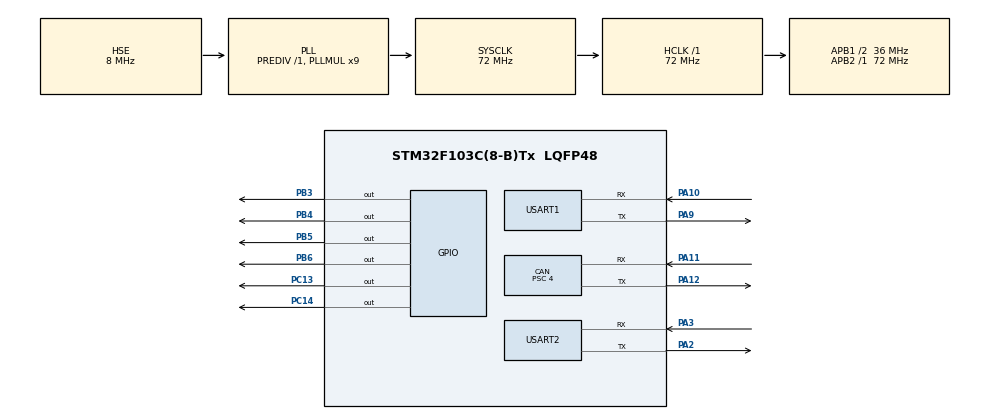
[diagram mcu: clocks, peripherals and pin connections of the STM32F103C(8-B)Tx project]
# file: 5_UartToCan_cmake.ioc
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CAN.ABOM=ENABLE
CAN.BS1=CAN_BS1_13TQ
CAN.BS2=CAN_BS2_4TQ
CAN.CalculateBaudRate=500000
CAN.CalculateTimeBit=2000
CAN.CalculateTimeQuantum=111.11111111111111
CAN.NART=ENABLE
CAN.Prescaler=4
CAN.SJW=CAN_SJW_1TQ
CAN.TXFP=ENABLE
FREERTOS.Queues01=UartRxQueue,128,uint8_t,0,Dynamic,NULL,NULL;CanCmdQueue,128,CanCmd_t,0,Dynamic,NULL,NULL
FREERTOS.Tasks01=Heart_Ta,8,128,Start_Heart_Ta,Default,NULL,Static,Heart_TaBuffer,Heart_TaControlBlock;UartRx_Ta,24,256,Start_UartRx_Ta,Default,NULL,Static,UartRx_TaBuffer,UartRx_TaControlBlock;CanTx_Ta,24,256,Start_CanTx_Ta,Default,NULL,Static,CanTx_TaBuffer,CanTx_TaControlBlock
Mcu.Family=STM32F1
Mcu.Name=STM32F103C(8-B)Tx
Mcu.Package=LQFP48
NVIC.PriorityGroup=NVIC_PRIORITYGROUP_4
NVIC.TIM4_IRQn=true\:15\:0\:false\:false\:true\:false\:false\:true\:true
NVIC.TimeBase=TIM4_IRQn
NVIC.TimeBaseIP=TIM4
NVIC.USART1_IRQn=true\:5\:0\:false\:false\:true\:true\:true\:true\:true
NVIC.USART2_IRQn=true\:5\:0\:false\:false\:true\:true\:true\:true\:true
NVIC.USB_HP_CAN1_TX_IRQn=true\:5\:0\:false\:false\:true\:true\:true\:true\:true
NVIC.USB_LP_CAN1_RX0_IRQn=true\:5\:0\:false\:false\:true\:true\:true\:true\:true
PA10.Mode=Asynchronous
PA10.Signal=USART1_RX
PA11.Mode=CAN_Activate
PA11.Signal=CAN_RX
PA12.Mode=CAN_Activate
PA12.Signal=CAN_TX
PA13.Mode=Serial_Wire
PA13.Signal=SYS_JTMS-SWDIO
PA14.Mode=Serial_Wire
PA14.Signal=SYS_JTCK-SWCLK
PA2.Mode=Asynchronous
PA2.Signal=USART2_TX
PA3.Mode=Asynchronous
PA3.Signal=USART2_RX
PA9.Mode=Asynchronous
PA9.Signal=USART1_TX
PB3.PinState=GPIO_PIN_SET
PB3.Signal=GPIO_Output
PB4.PinState=GPIO_PIN_SET
PB4.Signal=GPIO_Output
PB5.PinState=GPIO_PIN_SET
PB5.Signal=GPIO_Output
PB6.PinState=GPIO_PIN_SET
PB6.Signal=GPIO_Output
PC13-TAMPER-RTC.PinState=GPIO_PIN_SET
PC13-TAMPER-RTC.Signal=GPIO_Output
PC14-OSC32_IN.PinState=GPIO_PIN_SET
PC14-OSC32_IN.Signal=GPIO_Output
PD0-OSC_IN.Mode=HSE-External-Oscillator
PD0-OSC_IN.Signal=RCC_OSC_IN
PD1-OSC_OUT.Mode=HSE-External-Oscillator
PD1-OSC_OUT.Signal=RCC_OSC_OUT
ProjectManager.HeapSize=0x200
ProjectManager.StackSize=0x800
ProjectManager.TargetToolchain=CMake
RCC.AHBFreq_Value=72000000
RCC.APB1CLKDivider=RCC_HCLK_DIV2
RCC.APB1Freq_Value=36000000
RCC.APB1TimFreq_Value=72000000
RCC.APB2Freq_Value=72000000
RCC.APB2TimFreq_Value=72000000
RCC.EnbaleCSS=true
RCC.HCLKFreq_Value=72000000
RCC.PLLMUL=RCC_PLL_MUL9
RCC.PLLSourceVirtual=RCC_PLLSOURCE_HSE
RCC.SYSCLKFreq_VALUE=72000000
RCC.SYSCLKSource=RCC_SYSCLKSOURCE_PLLCLK
RCC.USBFreq_Value=72000000
USART1.VirtualMode=VM_ASYNC
USART2.VirtualMode=VM_ASYNC
VP_FREERTOS_VS_CMSIS_V2.Mode=CMSIS_V2
VP_SYS_VS_tim4.Mode=TIM4
board=custom

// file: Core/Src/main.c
/* USER CODE BEGIN Header */
/**
  ******************************************************************************
  * @file           : main.c
  * @brief          : Main program body
  ******************************************************************************
  * @attention
  *
  * Copyright (c) 2025 STMicroelectronics.
  * All rights reserved.
  *
  * This software is licensed under terms that can be found in the LICENSE file
  * in the root directory of this software component.
  * If no LICENSE file comes with this software, it is provided AS-IS.
  *
  ******************************************************************************
  */
/* USER CODE END Header */
#include "main.h"
#include "cmsis_os.h"
#include "can.h"
#include "usart.h"
#include "gpio.h"

/* USER CODE BEGIN Includes */
#include "app_task.h" // 新增：包含 app_task.h
/* USER CODE END Includes */

void SystemClock_Config(void);
void MX_FREERTOS_Init(void);

int main(void)
{

  /* MCU Configuration--------------------------------------------------------*/

  /* Reset of all peripherals, Initializes the Flash interface and the Systick. */
  HAL_Init();

  /* Configure the system clock */
  SystemClock_Config();

  /* Initialize all configured peripherals */
  MX_GPIO_Init();
  MX_CAN_Init();
  MX_USART1_UART_Init();
  MX_USART2_UART_Init();

  /* Init scheduler */
  osKernelInitialize();  /* Call init function for freertos objects (in cmsis_os2.c) */
  MX_FREERTOS_Init();

  /* Start scheduler */
  osKernelStart();

  /* We should never get here as control is now taken by the scheduler */

  /* Infinite loop */
  while (1)
  {

  }
}

void SystemClock_Config(void)
{
  RCC_OscInitTypeDef RCC_OscInitStruct = {0};
  RCC_ClkInitTypeDef RCC_ClkInitStruct = {0};

  /** Initializes the RCC Oscillators according to the specified parameters
  * in the RCC_OscInitTypeDef structure.
  */
  RCC_OscInitStruct.OscillatorType = RCC_OSCILLATORTYPE_HSE;
  RCC_OscInitStruct.HSEState = RCC_HSE_ON;
  RCC_OscInitStruct.HSEPredivValue = RCC_HSE_PREDIV_DIV1;
  RCC_OscInitStruct.HSIState = RCC_HSI_ON;
  RCC_OscInitStruct.PLL.PLLState = RCC_PLL_ON;
  RCC_OscInitStruct.PLL.PLLSource = RCC_PLLSOURCE_HSE;
  RCC_OscInitStruct.PLL.PLLMUL = RCC_PLL_MUL9;
  if (HAL_RCC_OscConfig(&RCC_OscInitStruct) != HAL_OK)
  {
    Error_Handler();
  }

  /** Initializes the CPU, AHB and APB buses clocks
  */
  RCC_ClkInitStruct.ClockType = RCC_CLOCKTYPE_HCLK|RCC_CLOCKTYPE_SYSCLK
                              |RCC_CLOCKTYPE_PCLK1|RCC_CLOCKTYPE_PCLK2;
  RCC_ClkInitStruct.SYSCLKSource = RCC_SYSCLKSOURCE_PLLCLK;
  RCC_ClkInitStruct.AHBCLKDivider = RCC_SYSCLK_DIV1;
  RCC_ClkInitStruct.APB1CLKDivider = RCC_HCLK_DIV2;
  RCC_ClkInitStruct.APB2CLKDivider = RCC_HCLK_DIV1;

  if (HAL_RCC_ClockConfig(&RCC_ClkInitStruct, FLASH_LATENCY_2) != HAL_OK)
  {
    Error_Handler();
  }

  /** Enables the Clock Security System
  */
  HAL_RCC_EnableCSS();
}

void HAL_TIM_PeriodElapsedCallback(TIM_HandleTypeDef *htim)
{
  if (htim->Instance == TIM4)
  {
    HAL_IncTick();
  }
}

void Error_Handler(void)
{
  __disable_irq();
  while (1)
  {
  }
}

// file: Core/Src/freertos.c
/* USER CODE BEGIN Header */
/**
  ******************************************************************************
  * File Name          : freertos.c
  * Description        : Code for freertos applications
  ******************************************************************************
  * @attention
  *
  * Copyright (c) 2025 STMicroelectronics.
  * All rights reserved.
  *
  * This software is licensed under terms that can be found in the LICENSE file
  * in the root directory of this software component.
  * If no LICENSE file comes with this software, it is provided AS-IS.
  *
  ******************************************************************************
  */
/* USER CODE END Header */

#include "FreeRTOS.h"
#include "task.h"
#include "main.h"
#include "cmsis_os.h"

/* USER CODE BEGIN Includes */

#include "app_task.h"

/* USER CODE END Includes */

typedef StaticTask_t osStaticThreadDef_t;

/* Definitions for Heart_Ta */
osThreadId_t Heart_TaHandle;
uint32_t Heart_TaBuffer[ 128 ];
osStaticThreadDef_t Heart_TaControlBlock;
const osThreadAttr_t Heart_Ta_attributes = {
  .name = "Heart_Ta",
  .cb_mem = &Heart_TaControlBlock,
  .cb_size = sizeof(Heart_TaControlBlock),
  .stack_mem = &Heart_TaBuffer[0],
  .stack_size = sizeof(Heart_TaBuffer),
  .priority = (osPriority_t) osPriorityLow,
};
/* Definitions for UartRx_Ta */
osThreadId_t UartRx_TaHandle;
uint32_t UartRx_TaBuffer[ 256 ];
osStaticThreadDef_t UartRx_TaControlBlock;
const osThreadAttr_t UartRx_Ta_attributes = {
  .name = "UartRx_Ta",
  .cb_mem = &UartRx_TaControlBlock,
  .cb_size = sizeof(UartRx_TaControlBlock),
  .stack_mem = &UartRx_TaBuffer[0],
  .stack_size = sizeof(UartRx_TaBuffer),
  .priority = (osPriority_t) osPriorityNormal,
};
/* Definitions for CanTx_Ta */
osThreadId_t CanTx_TaHandle;
uint32_t CanTx_TaBuffer[ 256 ];
osStaticThreadDef_t CanTx_TaControlBlock;
const osThreadAttr_t CanTx_Ta_attributes = {
  .name = "CanTx_Ta",
  .cb_mem = &CanTx_TaControlBlock,
  .cb_size = sizeof(CanTx_TaControlBlock),
  .stack_mem = &CanTx_TaBuffer[0],
  .stack_size = sizeof(CanTx_TaBuffer),
  .priority = (osPriority_t) osPriorityNormal,
};
/* Definitions for UartRxQueue */
osMessageQueueId_t UartRxQueueHandle;
const osMessageQueueAttr_t UartRxQueue_attributes = {
  .name = "UartRxQueue"
};
/* Definitions for CanCmdQueue */
osMessageQueueId_t CanCmdQueueHandle;
const osMessageQueueAttr_t CanCmdQueue_attributes = {
  .name = "CanCmdQueue"
};

void Start_Heart_Ta(void *argument);
void Start_UartRx_Ta(void *argument);
void Start_CanTx_Ta(void *argument);

void MX_FREERTOS_Init(void); /* (MISRA C 2004 rule 8.1) */

void MX_FREERTOS_Init(void) {

  /* Create the queue(s) */
  /* creation of UartRxQueue */
  UartRxQueueHandle = osMessageQueueNew (128, sizeof(uint8_t), &UartRxQueue_attributes);

  /* creation of CanCmdQueue */
  CanCmdQueueHandle = osMessageQueueNew (128, sizeof(CanCmd_t), &CanCmdQueue_attributes);

  /* Create the thread(s) */
  /* creation of Heart_Ta */
  Heart_TaHandle = osThreadNew(Start_Heart_Ta, NULL, &Heart_Ta_attributes);

  /* creation of UartRx_Ta */
  UartRx_TaHandle = osThreadNew(Start_UartRx_Ta, NULL, &UartRx_Ta_attributes);

  /* creation of CanTx_Ta */
  CanTx_TaHandle = osThreadNew(Start_CanTx_Ta, NULL, &CanTx_Ta_attributes);

}

void Start_Heart_Ta(void *argument)
{
  /* USER CODE BEGIN Start_Heart_Ta */
  /* Infinite loop */
  for(;;)
  {
    HAL_GPIO_TogglePin(GPIOC, GPIO_PIN_13);
    osDelay(200);
  }
  /* USER CODE END Start_Heart_Ta */
}

void Start_UartRx_Ta(void *argument)
{
  /* USER CODE BEGIN Start_UartRx_Ta */
  /* Infinite loop */

  UartRxTask(argument);

  // for(;;)
  // {
  //   osDelay(1);
  // }
  /* USER CODE END Start_UartRx_Ta */
}

void Start_CanTx_Ta(void *argument)
{
  /* USER CODE BEGIN Start_CanTx_Ta */
  /* Infinite loop */

  CanTxTask(argument);

  // for(;;)
  // {
  //   osDelay(1);
  // }
  /* USER CODE END Start_CanTx_Ta */
}
